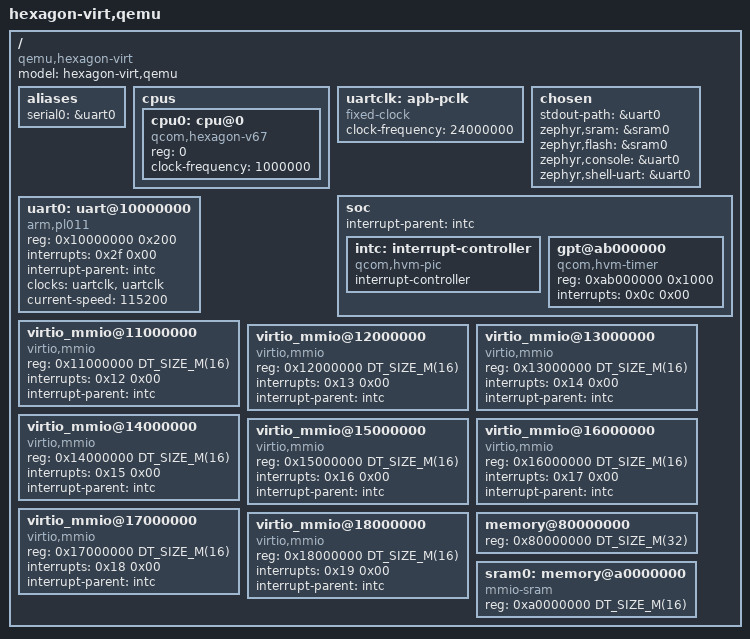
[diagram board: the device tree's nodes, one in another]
/*
 * Copyright (c) Qualcomm Technologies, Inc. and/or its subsidiaries.
 *
 * SPDX-License-Identifier: Apache-2.0
 */

/dts-v1/;

#include <mem.h>

/ {
	compatible = "qemu,hexagon-virt";
	model = "hexagon-virt,qemu";
	#address-cells = <1>;
	#size-cells = <1>;

	aliases {
		serial0 = &uart0;
	};

	cpus {
		#address-cells = <1>;
		#size-cells = <0>;

		cpu0: cpu@0 {
			compatible = "qcom,hexagon-v67";
			reg = <0>;
			device_type = "cpu";
			clock-frequency = <1000000>;
		};
	};

	uartclk: apb-pclk {
		compatible = "fixed-clock";
		clock-frequency = <24000000>;
		#clock-cells = <0>;
	};

	chosen {
		stdout-path = &uart0;
		zephyr,sram = &sram0;
		zephyr,flash = &sram0;
		zephyr,console = &uart0;
		zephyr,shell-uart = &uart0;
	};

	soc {
		ranges;
		#address-cells = <1>;
		#size-cells = <1>;
		interrupt-parent = <&intc>;

		intc: interrupt-controller {
			compatible = "qcom,hvm-pic";
			interrupt-controller;
			#interrupt-cells = <2>;
			#address-cells = <1>;
		};

		gpt@ab000000 {
			compatible = "qcom,hvm-timer";
			reg = <0xab000000 0x1000>;
			interrupts = <0x0c 0x00>;
		};
	};

	/* PL011 UART provided by QEMU virt machine */
	uart0: uart@10000000 {
		compatible = "arm,pl011", "arm,primecell";
		reg = <0x10000000 0x200>;
		interrupts = <0x2f 0x00>;
		interrupt-names = "irq_0";
		interrupt-parent = <&intc>;
		clocks = <&uartclk &uartclk>;
		clock-names = "uartclk", "apb_pclk";
		current-speed = <115200>;
		status = "okay";
	};

	/* VirtIO MMIO transports provided by QEMU virt machine */
	virtio_mmio@11000000 {
		compatible = "virtio,mmio";
		reg = <0x11000000 DT_SIZE_M(16)>;
		interrupts = <0x12 0x00>;
		interrupt-parent = <&intc>;
	};

	virtio_mmio@12000000 {
		compatible = "virtio,mmio";
		reg = <0x12000000 DT_SIZE_M(16)>;
		interrupts = <0x13 0x00>;
		interrupt-parent = <&intc>;
	};

	virtio_mmio@13000000 {
		compatible = "virtio,mmio";
		reg = <0x13000000 DT_SIZE_M(16)>;
		interrupts = <0x14 0x00>;
		interrupt-parent = <&intc>;
	};

	virtio_mmio@14000000 {
		compatible = "virtio,mmio";
		reg = <0x14000000 DT_SIZE_M(16)>;
		interrupts = <0x15 0x00>;
		interrupt-parent = <&intc>;
	};

	virtio_mmio@15000000 {
		compatible = "virtio,mmio";
		reg = <0x15000000 DT_SIZE_M(16)>;
		interrupts = <0x16 0x00>;
		interrupt-parent = <&intc>;
	};

	virtio_mmio@16000000 {
		compatible = "virtio,mmio";
		reg = <0x16000000 DT_SIZE_M(16)>;
		interrupts = <0x17 0x00>;
		interrupt-parent = <&intc>;
	};

	virtio_mmio@17000000 {
		compatible = "virtio,mmio";
		reg = <0x17000000 DT_SIZE_M(16)>;
		interrupts = <0x18 0x00>;
		interrupt-parent = <&intc>;
	};

	virtio_mmio@18000000 {
		compatible = "virtio,mmio";
		reg = <0x18000000 DT_SIZE_M(16)>;
		interrupts = <0x19 0x00>;
		interrupt-parent = <&intc>;
	};

	/* Main system memory */
	memory@80000000 {
		reg = <0x80000000 DT_SIZE_M(32)>;
		device_type = "memory";
	};

	/* SRAM for code and data */
	sram0: memory@a0000000 {
		compatible = "mmio-sram";
		reg = <0xa0000000 DT_SIZE_M(16)>;
		device_type = "memory";
	};
};
